# ISD91200B_v1 register map
File version: 1.0
Registers are 32-bit, read-write, reset 0x0 unless marked. A register's access mark holds for its fields unless they carry their own. Offsets are from the block's base; [hi:lo] are bit positions; {n}, {i} and the like mark numbered series; 'fields as' and 'values as' point back to an identical list.

## BOD — BOD Register Map
Base 0x40084000
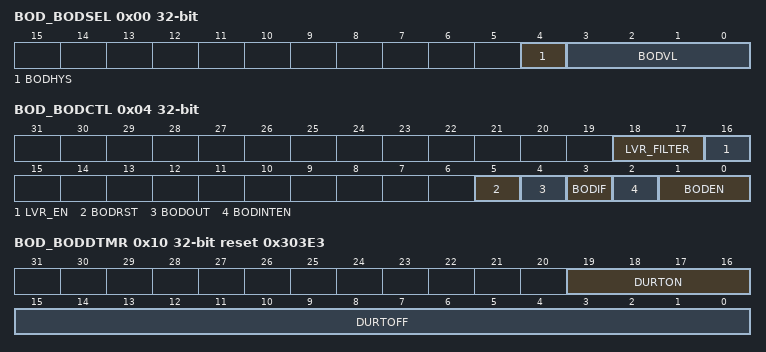
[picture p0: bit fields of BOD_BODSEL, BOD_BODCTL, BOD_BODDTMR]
0x00 BOD_BODSEL — Brown Out Detector Select Register
  [4] BODHYS — BOD Hysteresis
    0=Hysteresis Disabled; 1=Enable Hysteresis of BOD detection
  [3:0] BODVL — BOD Voltage Level
0x04 BOD_BODCTL (reset mask 0xFFF0FFF0) — Brown Out Detector Enable Register
  [18:17] LVR_FILTER — Default value is 00.
    0=LVR output will be filtered by 1 HCLK; 1=LVR output will be filtered by 2 HCLK; 2=LVR output will be filtered by 8 HCLK; 3=LVR output will be filtered by 15 HCLK
  [16] LVR_EN — Low Voltage Reset (LVR) Enable (Initialized & Protected Bit). The LVR function resets the chip when the input power voltage is lower than LVR trip point. Default value is set by flash controller as inverse of CLVR config0[27].
    0=Disable LVR function; 1=Enable LVR function
  [5] BODRST — BOD Reset. 1: Reset device when BOD is triggered.
  [4] BODOUT — Output of BOD Detection Block
  [3] BODIF — Current Status of Interrupt
  [2] BODINTEN — BOD Interrupt Enable
    0=Disable BOD Interrupt; 1=Enable BOD Interrupt
  [1:0] BODEN — BOD Enable
0x10 BOD_BODDTMR reset 0x303E3 — Brown Out Detector Timer Register
  [19:16] DURTON — Time BOD Detector Is Active (DURTON+1) * 100us. Minimum value is 1. (default is 400us)
  [15:0] DURTOFF — Time BOD Detector Is Off (DURTOFF+1)*100us . Minimum value is 7. (default is 99.6ms)

## I2C — I2C Register Map
Base 0x40020000
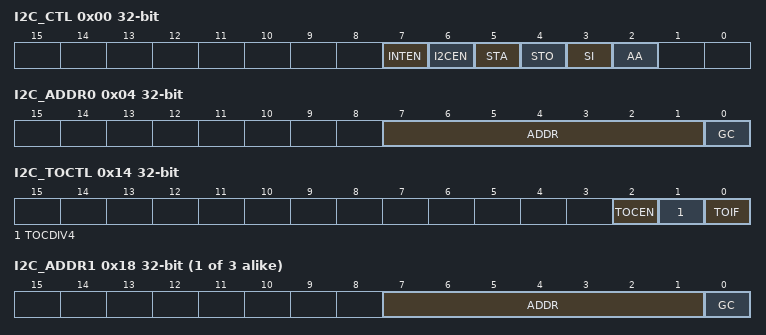
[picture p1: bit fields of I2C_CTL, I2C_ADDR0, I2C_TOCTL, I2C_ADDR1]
0x00 I2C_CTL — I2C Control Register
  [7] INTEN — Enable Interrupt
    0=Disable interrupt; 1=Enable interrupt CPU
  [6] I2CEN — I2C Controller Enable Bit. Set to enable I2C serial function block.
    0=Disable; 1=Enable
  [5] STA — I2C START Control Bit. Setting STA to logic 1 will enter master mode, the I2C hardware sends a START or repeat START condition to bus when the bus is free.
  [4] STO — I2C STOP Control Bit. In master mode, set STO to transmit a STOP condition to bus. I2C hardware will check the bus condition, when a STOP condition is detected this bit will be cleared by hardware automatically. In slave mode, setting STO resets I2C hardware to the defined "not addressed" slave mode. This means it is NO LONGER in the slave receiver mode able receive data from the master transmit device.
  [3] SI — I2C Interrupt Flag. When a new SIO state is present in the I2C_STATUS register, the SI flag is set by hardware, and if bit INTEN (I2C_CTL[7]) is set, the I2C interrupt is requested. SI must be cleared by software. Clear SI is by writing one to this bit.
  [2] AA — Assert Acknowledge Control Bit
0x04 I2C_ADDR0 — I2C Slave Address Register0
  [7:1] ADDR — I2C Address Register. The content of this register is irrelevant when I2C is in master mode. In the slave mode, the seven most significant bits must be loaded with the MCU's own address. The I2C hardware will react if any of the addresses are matched.
  [0] GC — General Call Function
    0=Disable General Call Function; 1=Enable General Call Function
0x08 I2C_DAT — I2C DATA Register
  [7:0] DAT — I2C Data Register. During master or slave transmit mode, data to be transmitted is written to this register. During master or slave receive mode, data that has been received may be read from this register.
0x0C I2C_STATUS ro reset 0xF8
  [7:0] STATUS — I2C Status Register. The status register of I2C:
0x10 I2C_CLKDIV — I2C Clock Divided Register
  [7:0] DIVIDER
0x14 I2C_TOCTL — I2C Time Out Control Register
  [2] TOCEN — Time-out Counter Control Bit. When enabled, the 14 bit time-out counter will start counting when SI is clear. Setting flag SI to high will reset counter and re-start up counting after SI is cleared.
    0=Disable; 1=Enable
  [1] TOCDIV4 — Time-out Counter Input Clock Divide by 4. When enabled, the time-out clock is PCLK/4.
    0=Disable; 1=Enable
  [0] TOIF — Time-out Flag
    0=No time-out; 1=Time-out flag is set by H/W. It can interrupt CPU. Write 1 to clear.
{0x14+4i} I2C_ADDR{i} (i=1..3) — I2C Slave Address Register{i}
  fields as I2C_ADDR0
{0x24+4i} I2C_ADDRMSK{i} (i=0..3) — I2C Slave Address Mask Register{i}
  [7:1] ADDRMSK — I2C Address Mask Register. I2C bus controllers support multiple-address recognition with four address mask registers. Bits in this field mask the ADDRx registers masking bits from the address comparison.
    0=Mask disable; 1=Mask enable (the received corresponding address bit is don't care.)
